# R7FA8M1AH register map
Vendor: Renesas; Series: RA8; File version: 1.2
CPU: CM85 r0p0, little endian, MPU, FPU, VTOR, 4 interrupt priority bits
Registers are 32-bit, read-write, reset 0x0 unless marked. A register's access mark holds for its fields unless they carry their own. Offsets are from the block's base; [hi:lo] are bit positions; {n}, {i} and the like mark numbered series; 'fields as' and 'values as' point back to an identical list.

## ELC — Event Link Controller
Base 0x40201000
Same registers: ELC_NS 0x50201000
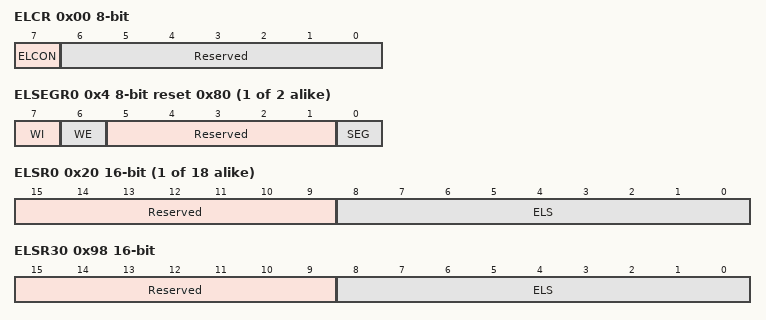
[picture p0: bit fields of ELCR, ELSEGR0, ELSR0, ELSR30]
0x00 ELCR 8-bit — Event Link Controller Register
  [7] ELCON — All Event Link Enable
    0=Disable ELC function; 1=Enable ELC function
  [6:0] Reserved — These bits are read as 0000000. The write value should be 0000000.
{0x4+4i} ELSEGR{i} (i=0..1) 8-bit reset 0x80 — Event Link Software Event Generation Register {i}
  [7] WI wo — ELSEGR Register Write Disable
    0=Enable writes to ELSEGR register; 1=Disable writes to ELSEGR register
  [6] WE — SEG Bit Write Enable
    0=Disable writes to SEG bit; 1=Enable writes to SEG bit
  [5:1] Reserved — These bits are read as 00000. The write value should be 00000.
  [0] SEG wo — Software Event Generation
    0=Normal operation; 1=Generate a software event
{0x20+4i} ELSR{i} (i=0..17) 16-bit — Event Link Setting Register {i}
  [15:9] Reserved — These bits are read as 0000000. The write value should be 0000000.
  [8:0] ELS — Event Link Select
    0=Event output to the corresponding peripheral module is disabled; other=others (Set the number for the event signal to be linked.)
0x98 ELSR30 16-bit — Event Link Setting Register 30
  fields as ELSR0
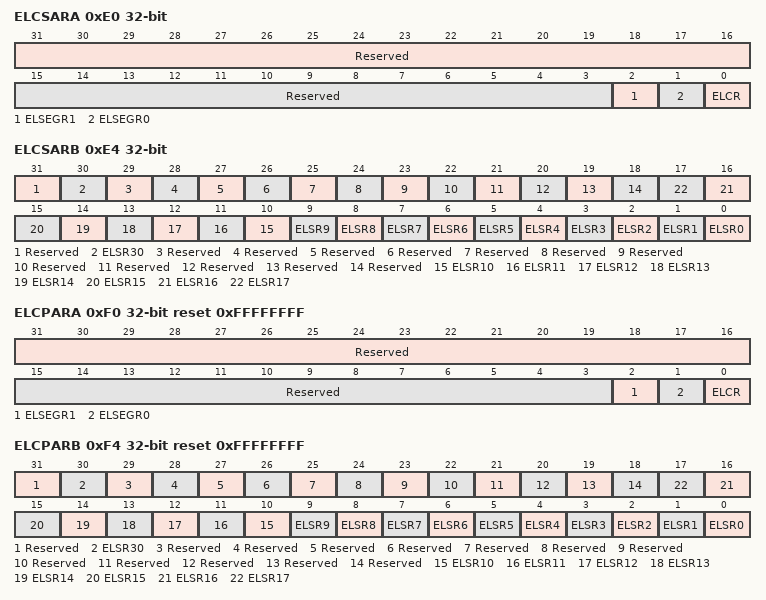
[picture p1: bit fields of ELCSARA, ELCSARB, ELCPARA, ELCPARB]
0xE0 ELCSARA — Event Link Controller Security Attribution Register A
  [31:16] Reserved — These bits are read as 0000000000000000. The write value should be 0000000000000000.
  [15:3] Reserved — These bits are read as 0000000000000. The write value should be 0000000000000.
  [2] ELSEGR1 — Event Link Software Event Generation Register 1Security Attribution
    0=Secure; 1=NonSecure
  [1] ELSEGR0 — Event Link Software Event Generation Register 0Security Attribution
    0=Secure; 1=NonSecure
  [0] ELCR — Event Link Controller RegisterSecurity Attribution
    0=Secure; 1=NonSecure
0xE4 ELCSARB — Event Link Controller Security Attribution Register B
  [31] Reserved — This bit is read as 0. The write value should be 0.
  [30] ELSR30 — Event Link Setting Register 30Security Attribution
    0=Secure; 1=NonSecure
  [29] Reserved — This bit is read as 0. The write value should be 0.
  [28] Reserved — This bit is read as 0. The write value should be 0.
  [27] Reserved — This bit is read as 0. The write value should be 0.
  [26] Reserved — This bit is read as 0. The write value should be 0.
  [25] Reserved — This bit is read as 0. The write value should be 0.
  [24] Reserved — This bit is read as 0. The write value should be 0.
  [23] Reserved — This bit is read as 0. The write value should be 0.
  [22] Reserved — This bit is read as 0. The write value should be 0.
  [21] Reserved — This bit is read as 0. The write value should be 0.
  [20] Reserved — This bit is read as 0. The write value should be 0.
  [19] Reserved — This bit is read as 0. The write value should be 0.
  [18] Reserved — This bit is read as 0. The write value should be 0.
  [n] ELSR{n} (n=0..17) — Event Link Setting Register {n}Security Attribution
    0=Secure; 1=NonSecure
0xF0 ELCPARA reset 0xFFFFFFFF — Event Link Controller Priviledge Attribution Register A
  [31:16] Reserved — These bits are read as 1111111111111111. The write value should be 1111111111111111.
  [15:3] Reserved — These bits are read as 1111111111111. The write value should be 1111111111111.
  [2] ELSEGR1 — Event Link Software Event Generation Register 1Priviledge Attribution
    0=Priviledge; 1=AnyPriviledge
  [1] ELSEGR0 — Event Link Software Event Generation Register 0Priviledge Attribution
    0=Priviledge; 1=AnyPriviledge
  [0] ELCR — Event Link Controller RegisterPriviledge Attribution
    0=Priviledge; 1=AnyPriviledge
0xF4 ELCPARB reset 0xFFFFFFFF — Event Link Controller Priviledge Attribution Register B
  [31] Reserved — This bit is read as 1. The write value should be 1.
  [30] ELSR30 — Event Link Setting Register 30Priviledge Attribution
    0=Priviledge; 1=AnyPriviledge
  [29] Reserved — This bit is read as 1. The write value should be 1.
  [28] Reserved — This bit is read as 1. The write value should be 1.
  [27] Reserved — This bit is read as 1. The write value should be 1.
  [26] Reserved — This bit is read as 1. The write value should be 1.
  [25] Reserved — This bit is read as 1. The write value should be 1.
  [24] Reserved — This bit is read as 1. The write value should be 1.
  [23] Reserved — This bit is read as 1. The write value should be 1.
  [22] Reserved — This bit is read as 1. The write value should be 1.
  [21] Reserved — This bit is read as 1. The write value should be 1.
  [20] Reserved — This bit is read as 1. The write value should be 1.
  [19] Reserved — This bit is read as 1. The write value should be 1.
  [18] Reserved — This bit is read as 1. The write value should be 1.
  [n] ELSR{n} (n=0..17) — Event Link Setting Register {n}Priviledge Attribution
    0=Priviledge; 1=AnyPriviledge
